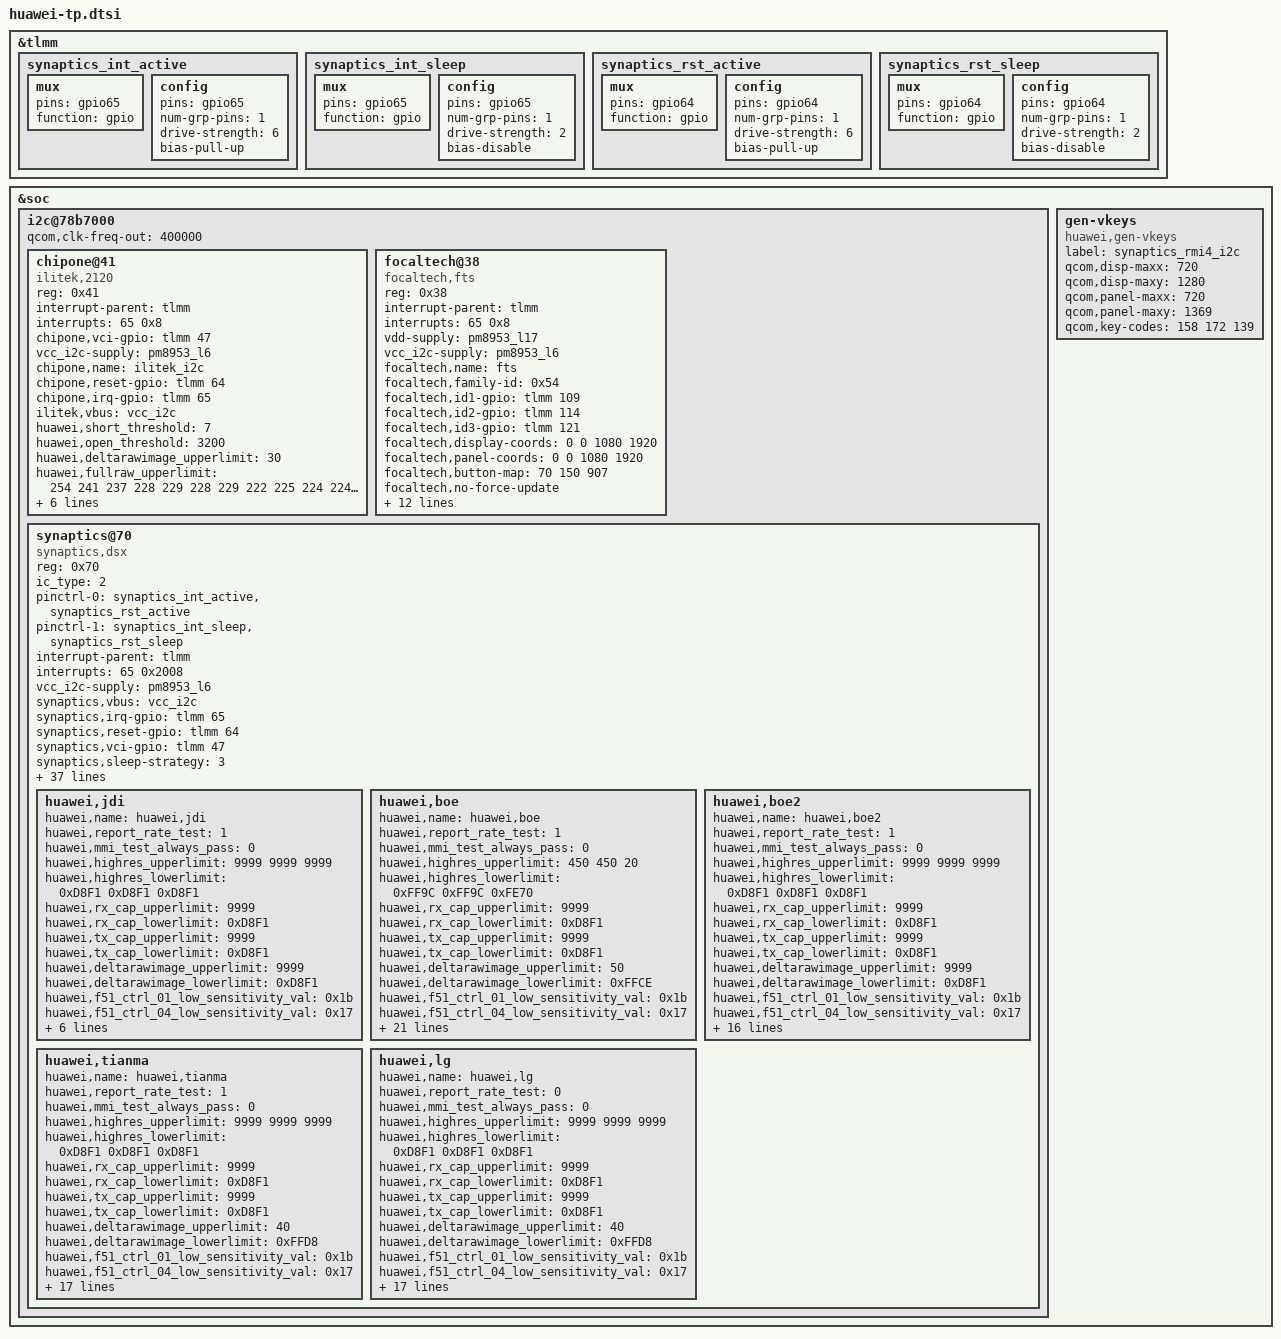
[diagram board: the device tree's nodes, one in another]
/* Modify JDI tp/lcd power on/off to reduce power consumption */
/* Modify JDI tp reset gpio pinctrl for power consumption */
/*Ath TP not working in glove mode*/
/* move l16 control to ATH device config file */
&tlmm {
	synaptics_int_active: synaptics_int_active{
			mux {
				pins = "gpio65";
				function =  "gpio";
			};
			config {
				pins = "gpio65";
				num-grp-pins = <1>;
				drive-strength = <6>;
				bias-pull-up;
		};
	};
	synaptics_int_sleep: synaptics_int_sleep {
			mux {
				pins = "gpio65";
				function =  "gpio";
			};
			config {
				pins = "gpio65";
				num-grp-pins = <1>;
				drive-strength = <2>;
				bias-disable;
		};
	};
	synaptics_rst_active: synaptics_rst_active {
			mux {
				pins = "gpio64";
				function =  "gpio";
			};
			config {
				pins = "gpio64";
				num-grp-pins = <1>;
				drive-strength = <6>;
				bias-pull-up;
			};
		};
	synaptics_rst_sleep: synaptics_rst_sleep {
			mux {
				pins = "gpio64";
				function =  "gpio";
			};
			config {
				pins = "gpio64";
				num-grp-pins = <1>;
				drive-strength = <2>;
				bias-disable;
		};
	};
};

&soc {
	i2c@78b7000 { /* BLSP1 QUP5 */
		status = "ok";
		#address-cells = <1>;
		#size-cells = <0>;
		qcom,clk-freq-out = <400000>;
		chipone@41{
			compatible = "ilitek,2120";
			reg = <0x41>;
			interrupt-parent = <&tlmm>;
			interrupts = <65 0x8>;
			chipone,vci-gpio = <&tlmm 47 0x0>;
			vcc_i2c-supply = <&pm8953_l6>;
			chipone,name = "ilitek_i2c";
			chipone,reset-gpio = <&tlmm 64 0x00>;
			chipone,irq-gpio = <&tlmm 65 0x00>;
			ilitek,vbus = "vcc_i2c";
			huawei,short_threshold = <7>;
			huawei,open_threshold = <3200>;
			huawei,deltarawimage_upperlimit = <30>;
			huawei,fullraw_upperlimit =
				<254 241 237 228 229 228 229 222 225 224 224 220 220 235 252
				247 234 232 219 219 220 220 216 218 217 216 214 213 228 246
				247 232 228 218 219 219 219 214 216 214 216 213 212 228 244
				247 232 228 218 220 218 219 214 216 214 214 212 212 226 244
				247 232 228 218 220 220 220 216 216 214 216 213 212 226 244
				247 231 228 219 218 219 219 214 217 214 216 213 212 226 244
				247 232 228 218 220 218 219 214 216 214 216 213 212 228 246
				247 232 228 219 219 218 219 214 216 216 216 213 212 226 244
				247 232 226 218 219 219 219 214 217 216 214 213 212 226 244
				247 231 226 218 219 218 218 214 216 214 214 213 212 228 244
				247 232 228 218 219 218 219 214 216 214 214 214 213 226 244
				247 231 226 218 219 218 219 216 216 214 214 214 213 228 246
				247 231 228 217 218 218 218 216 214 214 214 214 213 229 246
				249 235 230 219 222 222 222 219 218 218 218 218 217 231 248
				246 232 228 217 218 217 219 216 216 214 216 214 213 229 246
				247 231 226 217 218 218 219 216 214 214 216 216 214 230 246
				247 231 226 218 218 219 219 216 214 216 216 216 214 231 246
				247 231 226 217 218 217 218 217 216 214 216 214 214 230 246
				246 231 228 217 218 217 218 216 216 216 216 216 214 230 246
				247 231 225 217 218 217 218 216 216 214 216 216 214 231 247
				246 230 226 216 217 217 218 217 214 214 214 216 214 232 247
				246 230 226 217 218 217 218 216 214 214 214 216 214 233 246
				246 231 226 217 218 217 218 216 216 214 216 214 214 233 247
				246 231 225 216 218 217 217 216 214 214 216 216 214 229 246
				246 231 226 217 218 218 217 216 214 214 216 214 214 229 246
				246 231 226 218 218 218 218 216 214 214 214 216 214 228 246
				253 238 235 225 226 226 226 224 224 223 224 223 222 236 253>;

			huawei,fullraw_lowerlimit =
				<142 132 132 125 127 128 127 128 128 128 127 127 127 134 141
				139 128 129 121 124 124 123 124 125 125 124 123 123 130 137
				138 128 129 121 123 124 122 124 124 124 124 123 123 131 138
				138 128 128 120 123 124 123 124 124 125 124 123 122 130 136
				139 128 128 122 123 124 122 124 124 123 124 122 122 128 136
				138 128 128 121 123 123 122 124 124 124 123 122 122 127 135
				138 128 128 121 123 124 123 123 124 123 124 122 120 129 136
				139 128 128 121 123 124 123 124 124 125 123 121 120 128 134
				138 128 128 121 124 124 123 124 124 124 123 121 120 128 133
				136 128 128 121 124 124 122 123 124 122 122 121 119 127 133
				138 128 128 121 123 123 123 122 124 124 122 121 120 127 133
				137 128 128 121 123 124 122 124 124 123 123 121 121 129 135
				138 128 128 121 124 123 122 124 121 122 123 121 123 130 135
				138 129 130 123 124 125 124 125 125 126 125 126 124 130 136
				137 128 128 121 123 124 122 124 124 123 123 124 122 129 136
				137 128 128 121 123 124 122 123 124 123 123 124 123 130 136
				137 128 128 121 123 123 122 123 122 124 123 124 123 132 136
				138 128 128 121 123 123 122 124 124 124 124 124 123 132 136
				136 128 128 121 123 123 122 123 124 124 123 124 123 131 135
				136 128 127 121 122 123 122 124 124 123 124 124 123 131 136
				135 128 128 121 121 123 123 124 122 124 122 124 123 132 136
				133 128 128 121 122 124 122 124 121 123 123 124 123 132 135
				135 128 127 121 123 123 122 124 123 122 124 123 123 132 136
				134 128 126 121 121 124 122 124 122 122 124 123 122 129 134
				133 128 127 120 122 124 122 124 120 120 123 121 121 127 133
				134 128 126 121 121 122 123 123 120 121 121 122 121 127 132
				136 132 132 124 125 128 127 127 126 126 128 126 124 130 136>;

			huawei,rx_cap_upperlimit =
				<30 10 20 10 10 10 15 10 10 15 15 10 30 30
				30 10 20 10 10 10 15 10 10 15 15 10 30 30
				30 10 20 10 10 10 15 10 10 15 15 10 30 30
				30 10 20 10 10 10 15 10 10 15 15 10 30 30
				30 10 20 10 10 10 15 10 10 15 15 10 30 30
				30 10 20 10 10 10 15 10 10 15 15 10 30 30
				30 10 20 10 10 10 15 10 10 15 15 10 30 30
				30 10 20 10 10 10 15 10 10 15 15 10 30 30
				30 10 20 10 10 10 15 10 10 15 15 10 30 30
				30 10 20 10 10 10 15 10 10 15 15 10 30 30
				30 10 20 10 10 10 15 10 10 15 15 10 30 30
				30 10 20 10 10 10 15 10 10 15 15 10 30 30
				30 10 20 10 10 10 15 10 10 15 15 10 30 30
				30 10 20 10 10 10 15 10 10 15 15 10 30 30
				30 10 20 10 10 10 15 10 10 15 15 10 30 30
				30 10 20 10 10 10 15 10 10 15 15 10 30 30
				30 10 20 10 10 10 15 10 10 15 15 10 30 30
				30 10 20 10 10 10 15 10 10 15 15 10 30 30
				30 10 20 10 10 10 15 10 10 15 15 10 30 30
				30 10 20 10 10 10 15 10 10 15 15 10 30 30
				30 10 20 10 10 10 15 10 10 15 15 10 30 30
				30 10 20 10 10 10 15 10 10 15 15 10 30 30
				30 10 20 10 10 10 15 10 10 15 15 10 30 30
				30 10 20 10 10 10 15 10 10 15 15 10 30 30
				30 10 20 10 10 10 15 10 10 15 15 10 30 30
				30 10 20 10 10 10 15 10 10 15 15 10 30 30
				30 10 20 10 10 10 15 10 10 15 15 10 30 30>;

			huawei,tx_cap_upperlimit =
				<20 20 20 20 20 20 20 20 20 20 20 20 20 20 20
				10 10 10 10 10 10 10 10 10 10 10 10 10 10 10
				10 10 10 10 10 10 10 10 10 10 10 10 10 10 10
				10 10 10 10 10 10 10 10 10 10 10 10 10 10 10
				10 10 10 10 10 10 10 10 10 10 10 10 10 10 10
				10 10 10 10 10 10 10 10 10 10 10 10 10 10 10
				10 10 10 10 10 10 10 10 10 10 10 10 10 10 10
				10 10 10 10 10 10 10 10 10 10 10 10 10 10 10
				10 10 10 10 10 10 10 10 10 10 10 10 10 10 10
				10 10 10 10 10 10 10 10 10 10 10 10 10 10 10
				10 10 10 10 10 10 10 10 10 10 10 10 10 10 10
				10 10 10 10 10 10 10 10 10 10 10 10 10 10 10
				15 15 15 15 15 15 15 15 15 15 15 15 15 15 15
				15 15 15 15 15 15 15 15 15 15 15 15 15 15 15
				10 10 10 10 10 10 10 10 10 10 10 10 10 10 10
				10 10 10 10 10 10 10 10 10 10 10 10 10 10 10
				10 10 10 10 10 10 10 10 10 10 10 10 10 10 10
				10 10 10 10 10 10 10 10 10 10 10 10 10 10 10
				10 10 10 10 10 10 10 10 10 10 10 10 10 10 10
				10 10 10 10 10 10 10 10 10 10 10 10 10 10 10
				10 10 10 10 10 10 10 10 10 10 10 10 10 10 10
				10 10 10 10 10 10 10 10 10 10 10 10 10 10 10
				10 10 10 10 10 10 10 10 10 10 10 10 10 10 10
				10 10 10 10 10 10 10 10 10 10 10 10 10 10 10
				10 10 10 10 10 10 10 10 10 10 10 10 10 10 10
				20 20 20 20 20 20 20 20 20 20 20 20 20 20 20>;
		};
		focaltech@38 {
		compatible = "focaltech,fts";
		reg = <0x38>;
		interrupt-parent = <&tlmm>;
		interrupts = <65 0x8>;
		vdd-supply = <&pm8953_l17>;
		vcc_i2c-supply = <&pm8953_l6>;
		focaltech,name = "fts";
		focaltech,family-id = <0x54>;
		//focaltech,reset-gpio = <&tlmm 64 0x00>;
		//focaltech,irq-gpio =<&tlmm 65 0x00>;
		focaltech,id1-gpio = <&tlmm 109 0x00>;
		focaltech,id2-gpio = <&tlmm 114 0x00>;
		focaltech,id3-gpio = <&tlmm 121 0x00>;
		focaltech,display-coords = <0 0 1080 1920>;
		focaltech,panel-coords = <0 0 1080 1920>;
		focaltech,button-map= <70 150 907>;
		focaltech,no-force-update;
		focaltech,i2c-pull-up;
		focaltech,group-id = <1>;
		focaltech,hard-reset-delay-ms = <20>;
		focaltech,soft-reset-delay-ms = <150>;
		focaltech,num-max-touches = <10>;
		focaltech,fw-name = "FT_Upgrade_App.i";
		focaltech,fw-delay-aa-ms = <50>;
		focaltech,fw-delay-55-ms = <30>;
		focaltech,fw-upgrade-id1 = <0x79>;
		focaltech,fw-upgrade-id2 = <0x03>;
		focaltech,fw-delay-readid-ms = <10>;
		focaltech,fw-delay-era-flsh-ms = <2000>;
		};
		synaptics@70 {
			compatible = "synaptics,dsx";
			reg = <0x70>;

			/* SYNAPTICS_S3207 = 0 */
			/* SYNAPTICS_S3350 = 1 */
			/* SYNAPTICS_S3320 = 2 */
			/* SYNAPTICS_S3718 = 3 */
			ic_type = <2>;

			pinctrl-names = "active","sleep";
			pinctrl-0 = <&synaptics_int_active &synaptics_rst_active>;
			pinctrl-1 = <&synaptics_int_sleep &synaptics_rst_sleep>;

			interrupt-parent = <&tlmm>;
			interrupts = <65 0x2008>;
			//vdd-supply = <&pm8953_l17>;
			vcc_i2c-supply = <&pm8953_l6>;
			/* Some of qcom's param will not be replaced by huawei in dtb, */
			/* just ignore them:such as "pinctrl-names","pinctrl-0","pinctrl-1", */
			/* "synaptics,display-coords","synaptics,panel-coords","synaptics,i2c-pull-up", */
			/* "synaptics,power-down","synaptics,disable-gpios"*/
			//synaptics,vdd = "vdd";
			synaptics,vbus = "vcc_i2c";
			synaptics,irq-gpio = <&tlmm 65 0x2008>;
			synaptics,reset-gpio = <&tlmm 64 0x0>;
			synaptics,vci-gpio = <&tlmm 47 0x0>;

			/* synaptics,sleep/wake strategy */

			/* SLEEP_STRATEGY_DEEP_SLEEP    : 0*/
			/* SLEEP_STRATEGY_POWER_DOWN    : 1*/
			/* SLEEP_STRATEGY_KEEP_WAKE     : 2*/
			/* SLEEP_STRATEGY_ALWAYS_RESET  : 3*/
			synaptics,sleep-strategy = <3>;

			synaptics,lcd-x = <1080>;
			synaptics,lcd-y = <1920>;
			synaptics,lcd-all = <1920>;
			synaptics,virtual_keys = /* KeyCode CenterX CenterY Width Height */
				/* KEY_BACK */
				<158 142 1342 150 100
				/* KEY_HOME(172) */
				172 360 1342 150 100
				/* KEY_MENU */
				139 578 1342 150 100>;
			synaptics,shutdown_flag = <1>;
			synaptics,appinfo_display_flag = <1>;
			/* SYNAPTICS_WAKE_UP_GESTURE_FLAG:'1'->enabled,'0'->disabled */
			/*IC flash is not enough for holster,so fw del one gesture*/
			synaptics,gesture_enabled = <0>;
			/* Gestures that supported:                           */
			/* bit0  Double tap                                        */
			/* bit1  Single finger slide from left to right     */
			/* bit2  Single finger slide from right to left     */
			/* bit3  Single finger slide from top to bottom  */
			/* bit4  Single finger slide from bottom to top  */
			/* bit5  Double finger slide from top to bottom--disable for holster*/
			/* bit6  Single finger slide circle                     */
			/* bit7  Single finger write letter c                  */
			/* bit8  Single finger write letter e                  */
			/* bit9  Single finger write letter m                 */
			/* bit10 Single finger write letter w                 */
			/* bit11 Palm off screen                                */
			synaptics,easy_wakeup_supported_gestures = <0xF81>;

			/*Defination of report key value  for different gestures*/
			synaptics,easy_wakeup_gesture_keys =
			<	59 /*0.Double tap:                                  KEY_F1*/
				60 /*1.Single finger slide from left to right:      KEY_F2*/
				61 /*2.Single finger slide from right to left:      KEY_F3*/
				62 /*3.Single finger slide from top to bottom:      KEY_F4*/
				63 /*4.Single finger slide from bottom to top:      KEY_F5*/
				64 /*5.Single finger slide circle clockwise:        KEY_F6*/
				65 /*6.Single finger slide circle counter-clockwise:KEY_F7*/
				66 /*7.Single finger write letter c:                KEY_F8*/
				67 /*8.Single finger write letter e:                KEY_F9*/
				68 /*9.Single finger write letter m:                KEY_F10*/
				87 /*10.Single finger write letter w:               KEY_F11*/
				88 /*11.Palm off screen:                            KEY_F12*/
			>;

			/* Double-tap-zone defined by huawei */
			/* Shielded area is:1cm left,1cm right,3cm up,2cm down */
			huawei,dtz_x0 = <1>;
			huawei,dtz_y0 = <1>;
			huawei,dtz_x1 = <1080>;
			huawei,dtz_y1 = <1920>;

			/* GLOVE FLAG default state:'1'->enabled,'0'->disabled*/
			synaptics,glove_enabled = <0>;
			/*After reduce power-consumption by exit reduce mode,*/
			/*we have to reduce f-r rate to make sure gesture work fine*/
			synaptics,fast_relax_gesture = <0>;
			/*Holster support flag*/
			synaptics,holster_supported = <1>;
			synaptics,glove_edge_switch_supported = <0>;
			synaptics,grip_algorithm_supported = <0>;
			synaptics,grip_algorithm_enabled = <0>;
			huawei,grip_left_lsb = <0x32>;
			huawei,grip_left_msb = <0x0>;
			huawei,grip_right_lsb = <0x1A>;
			huawei,grip_right_msb = <0x04>;
			synaptics,roi_supported = <1>;
			synaptics,tx_rx_supported = <1>;
			huawei,tddi_esd_flag = <1>;
			/*dwt represent doze wakeup threshold in gesture mode*/
			synaptics,ofilm_dwt = <30>;
			synaptics,truly_dwt = <30>;
			synaptics,junda_dwt = <30>;

			synaptics,reset-on-status = <0>;
			synaptics,power-delay-ms = <160>;
			synaptics,reset-delay-ms = <200>;
			synaptics,reset-active-ms = <10>;
			synaptics,product_name = "cannes";

			/*capacitance self-adapt*/
			huawei,jdi {
				huawei,name = "huawei,jdi";
				huawei,report_rate_test = <1>; /* 0:disable test, 1:enable test */
				huawei,mmi_test_always_pass = <0>;

				huawei,highres_upperlimit = <9999 9999 9999>;
				huawei,highres_lowerlimit = <0xD8F1 0xD8F1 0xD8F1>;/* 0xD8F1 == -9999 */

				huawei,rx_cap_upperlimit = <9999>;
				huawei,rx_cap_lowerlimit = <0xD8F1>;

				huawei,tx_cap_upperlimit = <9999>;
				huawei,tx_cap_lowerlimit = <0xD8F1>;

				huawei,deltarawimage_upperlimit = <9999>;
				huawei,deltarawimage_lowerlimit = <0xD8F1>;

				huawei,f51_ctrl_01_low_sensitivity_val = <0x1b>;
				huawei,f51_ctrl_04_low_sensitivity_val = <0x17>;
				huawei,f01_ctrl_05_low_sensitivity_val = <0x05>;
				huawei,f01_ctrl_09_low_sensitivity_val = <0x04>;

				huawei,fullraw_upperlimit =
					<9999 9999 9999 9999 9999 9999 9999 9999 9999 9999 9999 9999 9999 9999 9999 9999 9999 9999 9999 9999 9999 9999 9999 9999 9999 9999 9999 9999
					9999 9999 9999 9999 9999 9999 9999 9999 9999 9999 9999 9999 9999 9999 9999 9999 9999 9999 9999 9999 9999 9999 9999 9999 9999 9999 9999 9999
					9999 9999 9999 9999 9999 9999 9999 9999 9999 9999 9999 9999 9999 9999 9999 9999 9999 9999 9999 9999 9999 9999 9999 9999 9999 9999 9999 9999
					9999 9999 9999 9999 9999 9999 9999 9999 9999 9999 9999 9999 9999 9999 9999 9999 9999 9999 9999 9999 9999 9999 9999 9999 9999 9999 9999 9999
					9999 9999 9999 9999 9999 9999 9999 9999 9999 9999 9999 9999 9999 9999 9999 9999 9999 9999 9999 9999 9999 9999 9999 9999 9999 9999 9999 9999
					9999 9999 9999 9999 9999 9999 9999 9999 9999 9999 9999 9999 9999 9999 9999 9999 9999 9999 9999 9999 9999 9999 9999 9999 9999 9999 9999 9999
					9999 9999 9999 9999 9999 9999 9999 9999 9999 9999 9999 9999 9999 9999 9999 9999 9999 9999 9999 9999 9999 9999 9999 9999 9999 9999 9999 9999
					9999 9999 9999 9999 9999 9999 9999 9999 9999 9999 9999 9999 9999 9999 9999 9999 9999 9999 9999 9999 9999 9999 9999 9999 9999 9999 9999 9999
					9999 9999 9999 9999 9999 9999 9999 9999 9999 9999 9999 9999 9999 9999 9999 9999 9999 9999 9999 9999 9999 9999 9999 9999 9999 9999 9999 9999
					9999 9999 9999 9999 9999 9999 9999 9999 9999 9999 9999 9999 9999 9999 9999 9999 9999 9999 9999 9999 9999 9999 9999 9999 9999 9999 9999 9999
					9999 9999 9999 9999 9999 9999 9999 9999 9999 9999 9999 9999 9999 9999 9999 9999 9999 9999 9999 9999 9999 9999 9999 9999 9999 9999 9999 9999
					9999 9999 9999 9999 9999 9999 9999 9999 9999 9999 9999 9999 9999 9999 9999 9999 9999 9999 9999 9999 9999 9999 9999 9999 9999 9999 9999 9999
					9999 9999 9999 9999 9999 9999 9999 9999 9999 9999 9999 9999 9999 9999 9999 9999 9999 9999 9999 9999 9999 9999 9999 9999 9999 9999 9999 9999
					9999 9999 9999 9999 9999 9999 9999 9999 9999 9999 9999 9999 9999 9999 9999 9999 9999 9999 9999 9999 9999 9999 9999 9999 9999 9999 9999 9999
					9999 9999 9999 9999 9999 9999 9999 9999 9999 9999 9999 9999 9999 9999 9999 9999 9999 9999 9999 9999 9999 9999 9999 9999 9999 9999 9999 9999
					9999 9999 9999 9999 9999 9999 9999 9999 9999 9999 9999 9999 9999 9999 9999 9999 9999 9999 9999 9999 9999 9999 9999 9999 9999 9999 9999 9999>;

				huawei,fullraw_lowerlimit =
					<0 0 0 0 0 0 0 0 0 0 0 0 0 0 0 0 0 0 0 0 0 0 0 0 0 0 0 0
					0 0 0 0 0 0 0 0 0 0 0 0 0 0 0 0 0 0 0 0 0 0 0 0 0 0 0 0
					0 0 0 0 0 0 0 0 0 0 0 0 0 0 0 0 0 0 0 0 0 0 0 0 0 0 0 0
					0 0 0 0 0 0 0 0 0 0 0 0 0 0 0 0 0 0 0 0 0 0 0 0 0 0 0 0
					0 0 0 0 0 0 0 0 0 0 0 0 0 0 0 0 0 0 0 0 0 0 0 0 0 0 0 0
					0 0 0 0 0 0 0 0 0 0 0 0 0 0 0 0 0 0 0 0 0 0 0 0 0 0 0 0
					0 0 0 0 0 0 0 0 0 0 0 0 0 0 0 0 0 0 0 0 0 0 0 0 0 0 0 0
					0 0 0 0 0 0 0 0 0 0 0 0 0 0 0 0 0 0 0 0 0 0 0 0 0 0 0 0
					0 0 0 0 0 0 0 0 0 0 0 0 0 0 0 0 0 0 0 0 0 0 0 0 0 0 0 0
					0 0 0 0 0 0 0 0 0 0 0 0 0 0 0 0 0 0 0 0 0 0 0 0 0 0 0 0
					0 0 0 0 0 0 0 0 0 0 0 0 0 0 0 0 0 0 0 0 0 0 0 0 0 0 0 0
					0 0 0 0 0 0 0 0 0 0 0 0 0 0 0 0 0 0 0 0 0 0 0 0 0 0 0 0
					0 0 0 0 0 0 0 0 0 0 0 0 0 0 0 0 0 0 0 0 0 0 0 0 0 0 0 0
					0 0 0 0 0 0 0 0 0 0 0 0 0 0 0 0 0 0 0 0 0 0 0 0 0 0 0 0
					0 0 0 0 0 0 0 0 0 0 0 0 0 0 0 0 0 0 0 0 0 0 0 0 0 0 0 0
					0 0 0 0 0 0 0 0 0 0 0 0 0 0 0 0 0 0 0 0 0 0 0 0 0 0 0 0>;
			};

			huawei,boe {
				huawei,name = "huawei,boe";
				huawei,report_rate_test = <1>; /* 0:disable test, 1:enable test */
				huawei,mmi_test_always_pass = <0>;

				huawei,highres_upperlimit = <450 450 20>;
				huawei,highres_lowerlimit = <0xFF9C 0xFF9C 0xFE70>;/*0xFF9C == -100 0xFE70 == -400 */

				huawei,rx_cap_upperlimit = <9999>;
				huawei,rx_cap_lowerlimit = <0xD8F1>;

				huawei,tx_cap_upperlimit = <9999>;
				huawei,tx_cap_lowerlimit = <0xD8F1>;

				huawei,deltarawimage_upperlimit = <50>;
				huawei,deltarawimage_lowerlimit = <0xFFCE>;

				huawei,f51_ctrl_01_low_sensitivity_val = <0x1b>;
				huawei,f51_ctrl_04_low_sensitivity_val = <0x17>;
				huawei,f01_ctrl_05_low_sensitivity_val = <0x05>;
				huawei,f01_ctrl_09_low_sensitivity_val = <0x04>;

				huawei,roi_control_addr_offset = <2>;
				huawei,roi_control_bit = <0>;
				huawei,roi_data_addr_offset = <24>;

				huawei,holster_switch_offset = <0>;
				huawei,set_effective_window_offset = <15>;
				huawei,holster_switch_glove_offset = <25>;
				huawei,support_set_window = <0>;
				huawei,support_3320short_test = <1>;
				huawei,trx_short_array_num = <4>;
				huawei,short_circuit_array = <0x00 0x00 0x00 0x00>;

				huawei,fullraw_upperlimit =
					<3447 3363 3309 3248 3208 3193 3177 3184 3190 3195 3194 3244 3314 3373 3487
					3306 3187 3126 3080 3043 3027 3013 3015 3013 3046 3025 3073 3136 3177 3289
					3314 3181 3111 3072 3032 3022 3016 3016 3007 3042 3025 3076 3111 3169 3298
					3316 3190 3117 3060 3020 3016 3020 3027 3016 3042 3030 3064 3111 3169 3306
					3321 3177 3114 3069 3025 3019 3025 3032 3022 3046 3043 3072 3116 3174 3308
					3328 3187 3117 3067 3030 3022 3027 3033 3027 3054 3046 3079 3117 3174 3312
					3330 3194 3121 3067 3030 3026 3032 3042 3027 3052 3050 3086 3138 3208 3312
					3328 3195 3126 3069 3036 3026 3037 3050 3037 3056 3057 3104 3168 3235 3309
					3314 3188 3120 3060 3033 3016 3037 3046 3033 3045 3052 3090 3168 3231 3292
					3322 3184 3123 3072 3033 3030 3037 3049 3033 3056 3064 3110 3178 3244 3302
					3315 3181 3114 3072 3026 3026 3032 3042 3027 3052 3063 3109 3169 3230 3292
					3312 3181 3114 3062 3027 3026 3032 3037 3027 3052 3050 3094 3153 3214 3282
					3306 3177 3106 3049 3020 3015 3022 3030 3019 3039 3045 3080 3141 3198 3274
					3295 3166 3094 3039 3010 3007 3013 3020 3016 3036 3033 3064 3136 3200 3262
					3288 3158 3091 3032 3004 3002 3002 3009 3007 3027 3015 3050 3109 3181 3253
					3274 3147 3079 3019 3000 2992 2989 3006 2996 3016 3009 3030 3073 3144 3244
					3261 3132 3062 3004 2995 2979 2978 2992 2983 3004 2992 3016 3057 3117 3230
					3241 3110 3050 2985 2972 2962 2958 2976 2968 2992 2976 3000 3025 3091 3208
					3228 3091 3033 2976 2953 2946 2943 2961 2953 2976 2961 2988 3009 3072 3193
					3207 3076 3020 2958 2943 2935 2929 2943 2942 2965 2941 2970 2996 3052 3171
					3184 3057 3007 2942 2931 2923 2911 2923 2929 2952 2922 2958 2995 3043 3151
					3158 3045 2990 2936 2928 2912 2901 2905 2914 2936 2904 2942 2989 3042 3132
					3134 3050 2990 2942 2935 2920 2906 2892 2896 2918 2884 2923 2985 3032 3109
					3116 3050 2989 2949 2936 2920 2908 2896 2881 2904 2868 2906 2968 3015 3084
					3116 3049 2979 2946 2938 2925 2908 2904 2888 2886 2875 2914 2973 3025 3060
					3109 3045 2998 2952 2938 2922 2911 2904 2894 2892 2881 2932 2998 3049 3043
					3314 3253 3207 3163 3130 3110 3109 3144 3088 3099 3088 3127 3195 3238 3253>;

				huawei,fullraw_lowerlimit =
					<1915 1738 1881 1856 1840 1839 1832 1840 1829 1814 1829 1826 1875 1910 1870
					1830 1671 1799 1768 1742 1727 1724 1713 1718 1712 1692 1718 1751 1793 1791
					1841 1679 1773 1743 1699 1695 1680 1684 1660 1679 1671 1696 1699 1742 1753
					1847 1687 1769 1760 1763 1756 1756 1747 1697 1744 1731 1756 1788 1830 1820
					1854 1693 1822 1796 1783 1783 1776 1780 1762 1748 1767 1793 1807 1850 1825
					1857 1700 1825 1789 1773 1756 1743 1755 1748 1751 1743 1732 1781 1834 1808
					1860 1702 1826 1784 1768 1751 1737 1751 1744 1747 1741 1730 1778 1830 1807
					1861 1706 1832 1791 1773 1756 1745 1758 1753 1756 1749 1738 1787 1840 1826
					1855 1700 1824 1799 1786 1786 1780 1789 1776 1762 1781 1803 1816 1863 1830
					1861 1711 1830 1807 1792 1784 1783 1774 1781 1763 1760 1788 1816 1868 1832
					1857 1711 1807 1760 1741 1720 1706 1715 1707 1708 1696 1685 1728 1780 1788
					1763 1712 1668 1631 1608 1592 1592 1579 1588 1585 1569 1599 1637 1686 1704
					1584 1569 1532 1492 1480 1468 1460 1479 1480 1491 1489 1492 1545 1608 1631
					1847 1707 1756 1720 1693 1679 1677 1664 1672 1668 1650 1677 1712 1760 1770
					1843 1704 1767 1737 1732 1732 1730 1717 1724 1718 1699 1725 1760 1805 1812
					1836 1700 1753 1732 1692 1687 1672 1684 1660 1664 1648 1675 1680 1722 1762
					1804 1697 1760 1730 1707 1697 1699 1690 1702 1700 1685 1716 1752 1801 1796
					1824 1690 1793 1769 1749 1737 1736 1724 1732 1725 1708 1735 1766 1812 1791
					1814 1687 1737 1707 1690 1682 1685 1685 1685 1685 1674 1668 1702 1751 1760
					1805 1682 1736 1722 1695 1679 1675 1661 1666 1656 1635 1657 1686 1725 1733
					1624 1578 1529 1494 1472 1462 1466 1457 1469 1469 1455 1486 1523 1574 1594
					1787 1674 1758 1732 1713 1704 1700 1696 1686 1684 1682 1679 1699 1748 1748
					1763 1668 1725 1695 1668 1651 1639 1636 1630 1634 1612 1636 1648 1692 1712
					1730 1660 1688 1657 1629 1612 1596 1609 1585 1588 1572 1594 1598 1641 1684
					1700 1635 1556 1553 1543 1536 1532 1552 1556 1553 1559 1590 1601 1656 1629
					1718 1718 1659 1606 1592 1584 1572 1596 1562 1562 1563 1563 1587 1640 1659
					1616 1599 1554 1517 1491 1488 1473 1476 1471 1475 1460 1484 1512 1548 1554>;
				huawei,tx_to_tx_limit =
					<275 275 275 275 275 275 275 275 275 275 275 275 275 275 275
					200 200	200 200	200 200	200 200 200 200 200 200 200 200 200
					200 200	200 200	200 200	200 200	200 200	200 200	200 200	200
					200 200	200 200	200 200	200 200	200 200	200 200	200 200	200
					200 200	200 200	200 200	200 200	200 200	200 200	200 200	200
					200 200	200 200	200 200	200 200	200 200	200 200	200 200	200
					200 200	200 200	200 200	200 200	200 200	200 200	200 200	200
					200 200	200 200	200 200	200 200	200 200	200 200	200 200	200
					200 200	200 200	200 200	200 200	200 200	200 200	200 200	200
					200 200	200 200	200 200	200 200	200 200	200 200	200 200	200
					200 200	200 200	200 200	200 200	200 200	200 200	200 200	200
					200 200	200 200	200 200	200 200	200 200	200 200	200 200	200
					200 200	200 200	200 200	200 200	200 200	200 200	200 200	200
					200 200	200 200	200 200	200 200	200 200	200 200	200 200	200
					200 200	200 200	200 200	200 200	200 200	200 200	200 200	200
					200 200	200 200	200 200	200 200	200 200	200 200	200 200	200
					200 200	200 200	200 200	200 200	200 200	200 200	200 200	200
					200 200	200 200	200 200	200 200	200 200	200 200	200 200	200
					200 200	200 200	200 200	200 200	200 200	200 200	200 200	200
					200 200	200 200	200 200	200 200	200 200	200 200	200 200	200
					200 200	200 200	200 200	200 200	200 200	200 200	200 200	200
					200 200	200 200	200 200	200 200	200 200	200 200	200 200	200
					200 200	200 200	200 200	200 200	200 200	200 200	200 200	200
					200 200	200 200	200 200	200 200	200 200	200 200	200 200	200
					200 200	200 200	200 200	200 200	200 200	200 200	200 200	200
					350 350	350 350	350 350	350 350	350 350	350 350	350 350	350>;
				huawei,rx_to_rx_limit =
					<250 250 250 250 250 250 250 250 250 250 250 250 250 250
					250 250 250 250 250 250 250 250 250 250 250 250 250 250
					250 250 250 250 250 250 250 250 250 250 250 250 250 250
					250 250 250 250 250 250 250 250 250 250 250 250 250 250
					250 250 250 250 250 250 250 250 250 250 250 250 250 250
					250 250 250 250 250 250 250 250 250 250 250 250 250 250
					250 250 250 250 250 250 250 250 250 250 250 250 250 250
					250 250 250 250 250 250 250 250 250 250 250 250 250 250
					250 250 250 250 250 250 250 250 250 250 250 250 250 250
					250 250 250 250 250 250 250 250 250 250 250 250 250 250
					250 250 250 250 250 250 250 250 250 250 250 250 250 250
					250 250 250 250 250 250 250 250 250 250 250 250 250 250
					250 250 250 250 250 250 250 250 250 250 250 250 250 250
					250 250 250 250 250 250 250 250 250 250 250 250 250 250
					250 250 250 250 250 250 250 250 250 250 250 250 250 250
					250 250 250 250 250 250 250 250 250 250 250 250 250 250
					250 250 250 250 250 250 250 250 250 250 250 250 250 250
					250 250 250 250 250 250 250 250 250 250 250 250 250 250
					250 250 250 250 250 250 250 250 250 250 250 250 250 250
					250 250 250 250 250 250 250 250 250 250 250 250 250 250
					250 250 250 250 250 250 250 250 250 250 250 250 250 250
					250 250 250 250 250 250 250 250 250 250 250 250 250 250
					250 250 250 250 250 250 250 250 250 250 250 250 250 250
					250 250 250 250 250 250 250 250 250 250 250 250 250 250
					250 250 250 250 250 250 250 250 250 250 250 250 250 250
					250 250 250 250 250 250 250 250 250 250 250 250 250 250
					250 250 250 250 250 250 250 250 250 250 250 250 250 250>;
			};
			huawei,boe2{
				huawei,name = "huawei,boe2";
				huawei,report_rate_test = <1>; /* 0:disable test, 1:enable test */
				// if is config item is set to 1, the mmi test will always return pass
				huawei,mmi_test_always_pass = <0>;

				huawei,highres_upperlimit = <9999 9999 9999>;
				huawei,highres_lowerlimit = <0xD8F1 0xD8F1 0xD8F1>;/* 0xD8F1 == -9999 */

				huawei,rx_cap_upperlimit = <9999>;
				huawei,rx_cap_lowerlimit = <0xD8F1>;

				huawei,tx_cap_upperlimit = <9999>;
				huawei,tx_cap_lowerlimit = <0xD8F1>;

				huawei,deltarawimage_upperlimit = <9999>;
				huawei,deltarawimage_lowerlimit = <0xD8F1>;

				huawei,f51_ctrl_01_low_sensitivity_val = <0x1b>;
				huawei,f51_ctrl_04_low_sensitivity_val = <0x17>;
				huawei,f01_ctrl_05_low_sensitivity_val = <0x05>;
				huawei,f01_ctrl_09_low_sensitivity_val = <0x04>;

				huawei,roi_control_addr_offset = <12>;
				huawei,roi_control_bit = <0>;
				huawei,roi_data_addr_offset = <0>;

				huawei,holster_switch_offset = <9>;
				huawei,set_effective_window_offset = <8>;
				huawei,support_set_window = <0>;

				huawei,fullraw_upperlimit =
					<9999 9999 9999 9999 9999 9999 9999 9999 9999 9999 9999 9999 9999 9999 9999 9999 9999 9999 9999 9999 9999 9999 9999 9999 9999 9999 9999 9999 9999 9999
					9999 9999 9999 9999 9999 9999 9999 9999 9999 9999 9999 9999 9999 9999 9999 9999 9999 9999 9999 9999 9999 9999 9999 9999 9999 9999 9999 9999 9999 9999
					9999 9999 9999 9999 9999 9999 9999 9999 9999 9999 9999 9999 9999 9999 9999 9999 9999 9999 9999 9999 9999 9999 9999 9999 9999 9999 9999 9999 9999 9999
					9999 9999 9999 9999 9999 9999 9999 9999 9999 9999 9999 9999 9999 9999 9999 9999 9999 9999 9999 9999 9999 9999 9999 9999 9999 9999 9999 9999 9999 9999
					9999 9999 9999 9999 9999 9999 9999 9999 9999 9999 9999 9999 9999 9999 9999 9999 9999 9999 9999 9999 9999 9999 9999 9999 9999 9999 9999 9999 9999 9999
					9999 9999 9999 9999 9999 9999 9999 9999 9999 9999 9999 9999 9999 9999 9999 9999 9999 9999 9999 9999 9999 9999 9999 9999 9999 9999 9999 9999 9999 9999
					9999 9999 9999 9999 9999 9999 9999 9999 9999 9999 9999 9999 9999 9999 9999 9999 9999 9999 9999 9999 9999 9999 9999 9999 9999 9999 9999 9999 9999 9999
					9999 9999 9999 9999 9999 9999 9999 9999 9999 9999 9999 9999 9999 9999 9999 9999 9999 9999 9999 9999 9999 9999 9999 9999 9999 9999 9999 9999 9999 9999
					9999 9999 9999 9999 9999 9999 9999 9999 9999 9999 9999 9999 9999 9999 9999 9999 9999 9999 9999 9999 9999 9999 9999 9999 9999 9999 9999 9999 9999 9999
					9999 9999 9999 9999 9999 9999 9999 9999 9999 9999 9999 9999 9999 9999 9999 9999 9999 9999 9999 9999 9999 9999 9999 9999 9999 9999 9999 9999 9999 9999
					9999 9999 9999 9999 9999 9999 9999 9999 9999 9999 9999 9999 9999 9999 9999 9999 9999 9999 9999 9999 9999 9999 9999 9999 9999 9999 9999 9999 9999 9999
					9999 9999 9999 9999 9999 9999 9999 9999 9999 9999 9999 9999 9999 9999 9999 9999 9999 9999 9999 9999 9999 9999 9999 9999 9999 9999 9999 9999 9999 9999
					9999 9999 9999 9999 9999 9999 9999 9999 9999 9999 9999 9999 9999 9999 9999 9999 9999 9999 9999 9999 9999 9999 9999 9999 9999 9999 9999 9999 9999 9999
					9999 9999 9999 9999 9999 9999 9999 9999 9999 9999 9999 9999 9999 9999 9999 9999 9999 9999 9999 9999 9999 9999 9999 9999 9999 9999 9999 9999 9999 9999
					9999 9999 9999 9999 9999 9999 9999 9999 9999 9999 9999 9999 9999 9999 9999 9999 9999 9999 9999 9999 9999 9999 9999 9999 9999 9999 9999 9999 9999 9999
					9999 9999 9999 9999 9999 9999 9999 9999 9999 9999 9999 9999 9999 9999 9999 9999 9999 9999 9999 9999 9999 9999 9999 9999 9999 9999 9999 9999 9999 9999
					9999 9999 9999 9999 9999 9999 9999 9999 9999 9999 9999 9999 9999 9999 9999 9999 9999 9999 9999 9999 9999 9999 9999 9999 9999 9999 9999 9999 9999 9999
					9999 9999 9999 9999 9999 9999 9999 9999 9999 9999 9999 9999 9999 9999 9999 9999 9999 9999 9999 9999 9999 9999 9999 9999 9999 9999 9999 9999 9999 9999>;

				huawei,fullraw_lowerlimit =
					<0 0 0 0 0 0 0 0 0 0 0 0 0 0 0 0 0 0 0 0 0 0 0 0 0 0 0 0 0 0
					0 0 0 0 0 0 0 0 0 0 0 0 0 0 0 0 0 0 0 0 0 0 0 0 0 0 0 0 0 0
					0 0 0 0 0 0 0 0 0 0 0 0 0 0 0 0 0 0 0 0 0 0 0 0 0 0 0 0 0 0
					0 0 0 0 0 0 0 0 0 0 0 0 0 0 0 0 0 0 0 0 0 0 0 0 0 0 0 0 0 0
					0 0 0 0 0 0 0 0 0 0 0 0 0 0 0 0 0 0 0 0 0 0 0 0 0 0 0 0 0 0
					0 0 0 0 0 0 0 0 0 0 0 0 0 0 0 0 0 0 0 0 0 0 0 0 0 0 0 0 0 0
					0 0 0 0 0 0 0 0 0 0 0 0 0 0 0 0 0 0 0 0 0 0 0 0 0 0 0 0 0 0
					0 0 0 0 0 0 0 0 0 0 0 0 0 0 0 0 0 0 0 0 0 0 0 0 0 0 0 0 0 0
					0 0 0 0 0 0 0 0 0 0 0 0 0 0 0 0 0 0 0 0 0 0 0 0 0 0 0 0 0 0
					0 0 0 0 0 0 0 0 0 0 0 0 0 0 0 0 0 0 0 0 0 0 0 0 0 0 0 0 0 0
					0 0 0 0 0 0 0 0 0 0 0 0 0 0 0 0 0 0 0 0 0 0 0 0 0 0 0 0 0 0
					0 0 0 0 0 0 0 0 0 0 0 0 0 0 0 0 0 0 0 0 0 0 0 0 0 0 0 0 0 0
					0 0 0 0 0 0 0 0 0 0 0 0 0 0 0 0 0 0 0 0 0 0 0 0 0 0 0 0 0 0
					0 0 0 0 0 0 0 0 0 0 0 0 0 0 0 0 0 0 0 0 0 0 0 0 0 0 0 0 0 0
					0 0 0 0 0 0 0 0 0 0 0 0 0 0 0 0 0 0 0 0 0 0 0 0 0 0 0 0 0 0
					0 0 0 0 0 0 0 0 0 0 0 0 0 0 0 0 0 0 0 0 0 0 0 0 0 0 0 0 0 0
					0 0 0 0 0 0 0 0 0 0 0 0 0 0 0 0 0 0 0 0 0 0 0 0 0 0 0 0 0 0
					0 0 0 0 0 0 0 0 0 0 0 0 0 0 0 0 0 0 0 0 0 0 0 0 0 0 0 0 0 0>;
				huawei,tx_to_tx_limit =
					<9999 9999 9999 9999 9999 9999 9999 9999 9999 9999 9999 9999 9999 9999 9999 9999 9999 9999 9999 9999 9999 9999 9999 9999 9999 9999 9999 9999 9999 9999
					9999 9999 9999 9999 9999 9999 9999 9999 9999 9999 9999 9999 9999 9999 9999 9999 9999 9999 9999 9999 9999 9999 9999 9999 9999 9999 9999 9999 9999 9999
					9999 9999 9999 9999 9999 9999 9999 9999 9999 9999 9999 9999 9999 9999 9999 9999 9999 9999 9999 9999 9999 9999 9999 9999 9999 9999 9999 9999 9999 9999
					9999 9999 9999 9999 9999 9999 9999 9999 9999 9999 9999 9999 9999 9999 9999 9999 9999 9999 9999 9999 9999 9999 9999 9999 9999 9999 9999 9999 9999 9999
					9999 9999 9999 9999 9999 9999 9999 9999 9999 9999 9999 9999 9999 9999 9999 9999 9999 9999 9999 9999 9999 9999 9999 9999 9999 9999 9999 9999 9999 9999
					9999 9999 9999 9999 9999 9999 9999 9999 9999 9999 9999 9999 9999 9999 9999 9999 9999 9999 9999 9999 9999 9999 9999 9999 9999 9999 9999 9999 9999 9999
					9999 9999 9999 9999 9999 9999 9999 9999 9999 9999 9999 9999 9999 9999 9999 9999 9999 9999 9999 9999 9999 9999 9999 9999 9999 9999 9999 9999 9999 9999
					9999 9999 9999 9999 9999 9999 9999 9999 9999 9999 9999 9999 9999 9999 9999 9999 9999 9999 9999 9999 9999 9999 9999 9999 9999 9999 9999 9999 9999 9999
					9999 9999 9999 9999 9999 9999 9999 9999 9999 9999 9999 9999 9999 9999 9999 9999 9999 9999 9999 9999 9999 9999 9999 9999 9999 9999 9999 9999 9999 9999
					9999 9999 9999 9999 9999 9999 9999 9999 9999 9999 9999 9999 9999 9999 9999 9999 9999 9999 9999 9999 9999 9999 9999 9999 9999 9999 9999 9999 9999 9999
					9999 9999 9999 9999 9999 9999 9999 9999 9999 9999 9999 9999 9999 9999 9999 9999 9999 9999 9999 9999 9999 9999 9999 9999 9999 9999 9999 9999 9999 9999
					9999 9999 9999 9999 9999 9999 9999 9999 9999 9999 9999 9999 9999 9999 9999 9999 9999 9999 9999 9999 9999 9999 9999 9999 9999 9999 9999 9999 9999 9999
					9999 9999 9999 9999 9999 9999 9999 9999 9999 9999 9999 9999 9999 9999 9999 9999 9999 9999 9999 9999 9999 9999 9999 9999 9999 9999 9999 9999 9999 9999
					9999 9999 9999 9999 9999 9999 9999 9999 9999 9999 9999 9999 9999 9999 9999 9999 9999 9999 9999 9999 9999 9999 9999 9999 9999 9999 9999 9999 9999 9999
					9999 9999 9999 9999 9999 9999 9999 9999 9999 9999 9999 9999 9999 9999 9999 9999 9999 9999 9999 9999 9999 9999 9999 9999 9999 9999 9999 9999 9999 9999
					9999 9999 9999 9999 9999 9999 9999 9999 9999 9999 9999 9999 9999 9999 9999 9999 9999 9999 9999 9999 9999 9999 9999 9999 9999 9999 9999 9999 9999 9999
					9999 9999 9999 9999 9999 9999 9999 9999 9999 9999 9999 9999 9999 9999 9999 9999 9999 9999 9999 9999 9999 9999 9999 9999 9999 9999 9999 9999 9999 9999>;
				huawei,rx_to_rx_limit =
					<9999 9999 9999 9999 9999 9999 9999 9999 9999 9999 9999 9999 9999 9999 9999 9999 9999 9999 9999 9999 9999 9999 9999 9999 9999 9999 9999 9999 9999
					9999 9999 9999 9999 9999 9999 9999 9999 9999 9999 9999 9999 9999 9999 9999 9999 9999 9999 9999 9999 9999 9999 9999 9999 9999 9999 9999 9999 9999
					9999 9999 9999 9999 9999 9999 9999 9999 9999 9999 9999 9999 9999 9999 9999 9999 9999 9999 9999 9999 9999 9999 9999 9999 9999 9999 9999 9999 9999
					9999 9999 9999 9999 9999 9999 9999 9999 9999 9999 9999 9999 9999 9999 9999 9999 9999 9999 9999 9999 9999 9999 9999 9999 9999 9999 9999 9999 9999
					9999 9999 9999 9999 9999 9999 9999 9999 9999 9999 9999 9999 9999 9999 9999 9999 9999 9999 9999 9999 9999 9999 9999 9999 9999 9999 9999 9999 9999
					9999 9999 9999 9999 9999 9999 9999 9999 9999 9999 9999 9999 9999 9999 9999 9999 9999 9999 9999 9999 9999 9999 9999 9999 9999 9999 9999 9999 9999
					9999 9999 9999 9999 9999 9999 9999 9999 9999 9999 9999 9999 9999 9999 9999 9999 9999 9999 9999 9999 9999 9999 9999 9999 9999 9999 9999 9999 9999
					9999 9999 9999 9999 9999 9999 9999 9999 9999 9999 9999 9999 9999 9999 9999 9999 9999 9999 9999 9999 9999 9999 9999 9999 9999 9999 9999 9999 9999
					9999 9999 9999 9999 9999 9999 9999 9999 9999 9999 9999 9999 9999 9999 9999 9999 9999 9999 9999 9999 9999 9999 9999 9999 9999 9999 9999 9999 9999
					9999 9999 9999 9999 9999 9999 9999 9999 9999 9999 9999 9999 9999 9999 9999 9999 9999 9999 9999 9999 9999 9999 9999 9999 9999 9999 9999 9999 9999
					9999 9999 9999 9999 9999 9999 9999 9999 9999 9999 9999 9999 9999 9999 9999 9999 9999 9999 9999 9999 9999 9999 9999 9999 9999 9999 9999 9999 9999
					9999 9999 9999 9999 9999 9999 9999 9999 9999 9999 9999 9999 9999 9999 9999 9999 9999 9999 9999 9999 9999 9999 9999 9999 9999 9999 9999 9999 9999
					9999 9999 9999 9999 9999 9999 9999 9999 9999 9999 9999 9999 9999 9999 9999 9999 9999 9999 9999 9999 9999 9999 9999 9999 9999 9999 9999 9999 9999
					9999 9999 9999 9999 9999 9999 9999 9999 9999 9999 9999 9999 9999 9999 9999 9999 9999 9999 9999 9999 9999 9999 9999 9999 9999 9999 9999 9999 9999
					9999 9999 9999 9999 9999 9999 9999 9999 9999 9999 9999 9999 9999 9999 9999 9999 9999 9999 9999 9999 9999 9999 9999 9999 9999 9999 9999 9999 9999
					9999 9999 9999 9999 9999 9999 9999 9999 9999 9999 9999 9999 9999 9999 9999 9999 9999 9999 9999 9999 9999 9999 9999 9999 9999 9999 9999 9999 9999
					9999 9999 9999 9999 9999 9999 9999 9999 9999 9999 9999 9999 9999 9999 9999 9999 9999 9999 9999 9999 9999 9999 9999 9999 9999 9999 9999 9999 9999
					9999 9999 9999 9999 9999 9999 9999 9999 9999 9999 9999 9999 9999 9999 9999 9999 9999 9999 9999 9999 9999 9999 9999 9999 9999 9999 9999 9999 9999>;

			};
			huawei,tianma{
				huawei,name = "huawei,tianma";
				huawei,report_rate_test = <1>; /* 0:disable test, 1:enable test */
				// if is config item is set to 1, the mmi test will always return pass
				huawei,mmi_test_always_pass = <0>;

				huawei,highres_upperlimit = <9999 9999 9999>;
				huawei,highres_lowerlimit = <0xD8F1 0xD8F1 0xD8F1>;/* 0xD8F1 == -9999 */

				huawei,rx_cap_upperlimit = <9999>;
				huawei,rx_cap_lowerlimit = <0xD8F1>;

				huawei,tx_cap_upperlimit = <9999>;
				huawei,tx_cap_lowerlimit = <0xD8F1>;

				huawei,deltarawimage_upperlimit = <40>;
				huawei,deltarawimage_lowerlimit = <0xFFD8>; /* 0xFFD8 == -40 */

				huawei,f51_ctrl_01_low_sensitivity_val = <0x1b>;
				huawei,f51_ctrl_04_low_sensitivity_val = <0x17>;
				huawei,f01_ctrl_05_low_sensitivity_val = <0x05>;
				huawei,f01_ctrl_09_low_sensitivity_val = <0x04>;

				huawei,roi_control_addr_offset = <12>;
				huawei,roi_control_bit = <0>;
				huawei,roi_data_addr_offset = <0>;

				huawei,holster_switch_offset = <9>;
				huawei,set_effective_window_offset = <8>;
				huawei,support_set_window = <0>;
				huawei,support_td43xxshort_test = <0>;

				huawei,fullraw_upperlimit =
					<2146 1955 2032 1901 1991 2023 2033 1949 1986 1928 1855 1914 1837 1802 2159 1985 1879 1874 1830 1772 1901 1814 1788 1865 1824 1776 1882 1824 1802 1914
					2021 1843 1945 1824 1907 1949 1951 1834 1837 1810 1711 1771 1698 1752 1916 1794 1736 1794 1759 1698 1820 1738 1710 1784 1738 1699 1807 1750 1722 1792
					1888 1692 1813 1726 1788 1801 1805 1704 1782 1706 1687 1711 1694 1769 1811 1794 1764 1799 1765 1708 1829 1746 1715 1801 1752 1699 1814 1748 1706 1782
					1822 1626 1718 1576 1637 1652 1668 1608 1753 1652 1682 1715 1698 1768 1805 1783 1769 1806 1776 1717 1834 1756 1727 1810 1760 1703 1818 1748 1702 1783
					1818 1634 1696 1535 1580 1622 1637 1607 1706 1672 1685 1727 1704 1734 1805 1790 1775 1824 1784 1726 1840 1768 1736 1811 1764 1702 1814 1748 1711 1788
					1837 1661 1699 1554 1573 1637 1649 1622 1722 1688 1692 1740 1710 1727 1813 1748 1736 1840 1790 1730 1852 1776 1744 1807 1769 1696 1811 1748 1710 1806
					1878 1687 1710 1615 1591 1657 1664 1638 1736 1698 1702 1753 1721 1776 1824 1759 1745 1848 1802 1744 1864 1780 1746 1811 1772 1699 1810 1750 1710 1843
					1951 1722 1872 1897 1867 1775 1664 1640 1740 1699 1702 1757 1726 1768 1822 1894 1846 1846 1802 1745 1865 1778 1745 1813 1775 1702 1810 1744 1702 1862
					2006 1778 1879 1906 1998 1940 1714 1654 1661 1666 1706 1696 1691 1756 1930 1960 1867 1776 1752 1744 1790 1730 1744 1738 1724 1699 1736 1696 1696 1799
					2077 1807 1753 1920 1939 1956 1876 1645 1661 1680 1729 1813 1876 1848 2012 1993 1825 1715 1736 1679 1775 1714 1706 1699 1668 1718 1745 1715 1646 1694
					2135 1849 1579 1820 1949 1930 1962 1727 1652 1768 2009 1967 2006 1936 1986 2040 1780 1711 1811 1727 1788 1865 1752 1704 1769 1855 1759 1802 1704 1694
					2110 1855 1760 1805 1771 1871 1956 1738 1640 1916 2084 1978 2009 1928 1769 1794 1775 1711 1907 1945 1878 1914 1752 1711 1805 1878 1799 1806 1776 1765
					2110 1883 1860 1955 1825 1811 1944 1757 1631 1936 2081 1968 2020 1936 1734 1837 1794 1706 2093 2005 1909 1962 1748 1710 1776 1760 1710 1805 1970 1817
					2093 1840 1871 1967 1895 1778 1913 1741 1829 1795 2005 1916 1926 1760 1691 1848 1883 1784 2152 2020 1939 1902 1744 1710 1778 1752 1706 1943 2082 1885
					2090 1740 1830 1949 1868 1848 1825 1841 1913 1933 1937 1910 1906 1692 1684 1778 1879 1813 2068 1979 1841 1778 1726 1706 1776 1740 1708 1981 2110 1932
					2068 1760 1598 1820 1836 1832 1790 1872 1906 1943 1939 1882 1974 1814 1718 1784 1788 1750 1974 1814 1830 1985 1841 1722 1775 1730 1711 2009 2100 1951
					1987 1748 1511 1627 1631 1660 1817 1879 1897 1936 1921 1886 2010 1939 1811 1822 1788 1682 1993 1846 2033 2082 1910 1795 1764 1718 1706 1846 1956 1757
					1872 1637 1589 1634 1631 1682 1860 1910 1920 1956 1960 1921 2054 2023 1966 1943 1886 1757 1830 2009 2105 2155 2036 1792 1855 1810 1805 1904 1836 1878>;

				huawei,fullraw_lowerlimit =
					<936 804 849 845 849 890 885 851 916 880 886 933 908 864 936 933 885 943 954 890 924 914 896 913 914 887 924 890 909 923
					872 740 794 791 791 830 824 798 870 834 839 890 867 819 895 890 844 908 918 850 890 880 862 875 875 847 894 862 870 867
					875 748 798 798 798 838 834 806 879 845 850 903 878 829 905 901 847 913 918 852 892 882 862 879 879 847 892 852 864 854
					880 747 802 798 798 839 836 810 882 850 852 907 882 834 906 905 852 918 923 862 898 886 866 883 885 851 896 860 862 867
					883 757 810 809 806 849 847 821 892 864 865 918 890 842 914 909 862 918 926 864 900 887 867 883 885 851 893 852 865 875
					885 759 814 811 809 851 850 822 894 865 866 918 890 844 914 910 860 918 926 865 898 886 866 883 885 849 894 851 866 890
					885 767 824 823 817 865 864 830 901 875 872 926 898 849 918 911 860 918 924 862 898 886 864 882 882 847 890 850 865 898
					882 770 828 828 823 869 869 834 906 878 874 924 895 847 915 910 851 914 920 854 894 882 862 878 879 842 886 845 851 892
					846 786 798 806 834 826 834 842 862 850 878 885 870 846 873 883 849 870 892 850 845 849 854 830 844 842 842 819 849 851
					959 854 859 873 882 857 924 878 929 906 898 924 952 895 962 938 920 946	933 938 952 949 918 938 939 910 942 944 916 964
					1005 865 842 903 900 846  962 903 922 946 924 920 993 921 957 982 950 950 982 969 952 997 950 938 1003 956 943 1000 952 954
					1002 849 819 883 880 831 946 890 913 931 920 913 992 920 956 982 950 954 985 974 954 999 952 952 1008 969 948 1006 959 954
					999 836	815 878 874 822 942 880 903 926 915 908 990 914 952 982 950 954 985 974 954 1000 956 950 1012 970 950 1010 966 951
					999 849	810 883 869 823 941 882 905 920 914 905 987 913 946 982 950 952 984 974 956 1002 957 951 1013 969 954 1010 969 943
					999 844	810 873 874 819 936 875 901 916 909 900 986 911 946 979 949 946 979 967 954 1000 957 946 1012 962 951 1006 965 929
					999 839	802 875 872 818 930 875 898 908 908 895 984 908 941 980 950 941 978 965 956 1002 957 943 1012 964 954 1003 964 929
					1002 838 814 875 873 815 931 870 895 913 907 890 979 906 941 977 950 934 974 962 956 1002 956 937 1003 954 951 1002 965 931
					1053 895 862 923 918 864 976 915 944 956 982 937 1028 957 987 1034 1006 987 1031 1018 1013 1059 1015 994 1066 1016 1014 1070 1043 1036>;
				huawei,tx_to_tx_limit =
					<250 250 250 250 250 250 250 250 250 250 250 250 250 250 250 250 250 250 250 250 250 250 250 250 250 250 250 250 250 250
					150 150 150 150 150 150 150 150 150 150 150 150 150 150 150 150 150 150 150 150 150 150 150 150 150 150 150 150 150 150
					150 150 150 150 150 150 150 150 150 150 150 150 150 150 150 150 150 150 150 150 150 150 150 150 150 150 150 150 150 150
					150 150 150 150 150 150 150 150 150 150 150 150 150 150 150 150 150 150 150 150 150 150 150 150 150 150 150 150 150 150
					200 200 200 200 200 200 200 200 200 200 200 200 200 200 200 200 200 200 200 200 200 200 200 200 200 200 200 200 200 200
					200 200 200 200 200 200 200 200 200 200 200 200 200 200 200 200 200 200 200 200 200 200 200 200 200 200 200 200 200 200
					200 200 200 200 200 200 200 200 200 200 200 200 200 200 200 200 200 200 200 200 200 200 200 200 200 200 200 200 200 200
					250 250 250 250 250 250 250 250 250 250 250 250 250 250 250 250 250 250 250 250 250 250 250 250 250 250 250 250 250 250
					300 300 300 300 300 300 300 300 300 300 300 300 300 300 300 300 300 300 300 300 300 300 300 300 300 300 300 300 300 300
					300 300 300 300 300 300 300 300 300 300 300 300 300 300 300 300 300 300 300 300 300 300 300 300 300 300 300 300 300 300
					200 200 200 200 200 200 200 200 200 200 200 200 200 200 200 200 200 200 200 200 200 200 200 200 200 200 200 200 200 200
					200 200 200 200 200 200 200 200 200 200 200 200 200 200 200 200 200 200 200 200 200 200 200 200 200 200 200 200 200 200
					200 200 200 200 200 200 200 200 200 200 200 200 200 200 200 200 200 200 200 200 200 200 200 200 200 200 200 200 200 200
					150 150 150 150 150 150 150 150 150 150 150 150 150 150 150 150 150 150 150 150 150 150 150 150 150 150 150 150 150 150
					150 150 150 150 150 150 150 150 150 150 150 150 150 150 150 150 150 150 150 150 150 150 150 150 150 150 150 150 150 150
					150 150 150 150 150 150 150 150 150 150 150 150 150 150 150 150 150 150 150 150 150 150 150 150 150 150 150 150 150 150
					350 350 350 350 350 350 350 350 350 350 350 350 350 350 350 350 350 350 350 350 350 350 350 350 350 350 350 350 350 350>;
				huawei,rx_to_rx_limit =
					<600 400 400 400 400 400 400 400 400 400 400 400 400 400 400 400 400 400 400 400 400 400 400 400 400 400 400 400 400
					600 400 400 400 400 400 400 400 400 400 400 400 400 400 400 400 400 400 400 400 400 400 400 400 400 400 400 400 400
					600 400 400 400 400 400 400 400 400 400 400 400 400 400 400 400 400 400 400 400 400 400 400 400 400 400 400 400 400
					600 400 400 400 400 400 400 400 400 400 400 400 400 400 400 400 400 400 400 400 400 400 400 400 400 400 400 400 400
					600 400 400 400 400 400 400 400 400 400 400 400 400 400 400 400 400 400 400 400 400 400 400 400 400 400 400 400 400
					600 400 400 400 400 400 400 400 400 400 400 400 400 400 400 400 400 400 400 400 400 400 400 400 400 400 400 400 400
					600 400 400 400 400 400 400 400 400 400 400 400 400 400 400 400 400 400 400 400 400 400 400 400 400 400 400 400 400
					600 400 400 400 400 400 400 400 400 400 400 400 400 400 400 400 400 400 400 400 400 400 400 400 400 400 400 400 400
					600 400 400 400 400 400 400 400 400 400 400 400 400 400 400 400 400 400 400 400 400 400 400 400 400 400 400 400 400
					600 400 400 400 400 400 400 400 400 400 400 400 400 400 400 400 400 400 400 400 400 400 400 400 400 400 400 400 400
					600 400 400 400 400 400 400 400 400 400 400 400 400 400 400 400 400 400 400 400 400 400 400 400 400 400 400 400 400
					600 400 400 400 400 400 400 400 400 400 400 400 400 400 400 400 400 400 400 400 400 400 400 400 400 400 400 400 400
					600 400 400 400 400 400 400 400 400 400 400 400 400 400 400 400 400 400 400 400 400 400 400 400 400 400 400 400 400
					600 400 400 400 400 400 400 400 400 400 400 400 400 400 400 400 400 400 400 400 400 400 400 400 400 400 400 400 400
					600 400 400 400 400 400 400 400 400 400 400 400 400 400 400 400 400 400 400 400 400 400 400 400 400 400 400 400 400
					600 400 400 400 400 400 400 400 400 400 400 400 400 400 400 400 400 400 400 400 400 400 400 400 400 400 400 400 400
					600 400 400 400 400 400 400 400 400 400 400 400 400 400 400 400 400 400 400 400 400 400 400 400 400 400 400 400 400
					600 400 400 400 400 400 400 400 400 400 400 400 400 400 400 400 400 400 400 400 400 400 400 400 400 400 400 400 400>;
			};
			huawei,lg {
				huawei,name = "huawei,lg";
				huawei,report_rate_test = <0>; /* 0:disable test, 1:enable test */
				// if is config item is set to 1, the mmi test will always return pass
				huawei,mmi_test_always_pass = <0>;

				huawei,highres_upperlimit = <9999 9999 9999>;
				huawei,highres_lowerlimit = <0xD8F1 0xD8F1 0xD8F1>;/* 0xD8F1 == -9999 */

				huawei,rx_cap_upperlimit = <9999>;
				huawei,rx_cap_lowerlimit = <0xD8F1>;

				huawei,tx_cap_upperlimit = <9999>;
				huawei,tx_cap_lowerlimit = <0xD8F1>;

				huawei,deltarawimage_upperlimit = <40>;
				huawei,deltarawimage_lowerlimit = <0xFFD8>; /* 0xFFD8 == -40 */

				huawei,f51_ctrl_01_low_sensitivity_val = <0x1b>;
				huawei,f51_ctrl_04_low_sensitivity_val = <0x17>;
				huawei,f01_ctrl_05_low_sensitivity_val = <0x05>;
				huawei,f01_ctrl_09_low_sensitivity_val = <0x04>;

				huawei,roi_control_addr_offset = <12>;
				huawei,roi_control_bit = <0>;
				huawei,roi_data_addr_offset = <0>;

				huawei,holster_switch_offset = <9>;
				huawei,set_effective_window_offset = <8>;
				huawei,support_set_window = <0>;
				huawei,support_td43xxshort_test = <1>;

				huawei,fullraw_upperlimit =
					<1892 1854 1754 1793 1838 1752 1773 1838 1739 1782 1816 1738 1747 1815 1700 1750 1751 1669 1664 1698 1580 1612 1613 1547 1521 1578 1446 1486 1502 1491
					1687 1749 1652 1694 1742 1659 1680 1746 1651 1694 1730 1654 1663 1730 1619 1667 1672 1590 1587 1625 1508 1542 1546 1478 1455 1515 1378 1422 1439 1427
					1667 1736 1641 1684 1733 1650 1672 1738 1642 1687 1725 1650 1664 1732 1617 1669 1676 1593 1591 1632 1513 1551 1555 1489 1464 1525 1388 1430 1448 1440
					1664 1733 1638 1681 1730 1647 1669 1736 1639 1685 1723 1646 1659 1726 1615 1667 1673 1587 1589 1629 1512 1547 1552 1486 1463 1525 1388 1429 1448 1439
					1655 1723 1629 1673 1723 1639 1663 1730 1634 1680 1717 1645 1660 1728 1615 1668 1681 1598 1599 1646 1530 1570 1577 1512 1487 1552 1416 1459 1477 1472
					1652 1717 1629 1672 1721 1638 1663 1729 1633 1678 1717 1642 1656 1723 1611 1665 1677 1591 1595 1642 1528 1568 1577 1509 1491 1556 1416 1461 1479 1474
					1651 1715 1620 1665 1716 1633 1658 1725 1630 1676 1716 1642 1658 1725 1613 1665 1684 1603 1607 1652 1542 1581 1594 1530 1512 1577 1439 1483 1503 1499
					1658 1716 1624 1664 1717 1634 1660 1724 1632 1674 1716 1641 1655 1721 1612 1664 1682 1600 1603 1650 1542 1580 1594 1530 1515 1577 1442 1486 1508 1504
					1595 1633 1617 1596 1619 1628 1583 1613 1628 1620 1632 1639 1602 1642 1615 1615 1613 1612 1568 1585 1557 1547 1535 1554 1489 1528 1477 1473 1469 1551
					1619 1581 1615 1607 1578 1607 1596 1582 1603 1612 1576 1616 1590 1593 1609 1612 1559 1600 1563 1544 1544 1547 1494 1524 1490 1468 1451 1473 1418 1533
					1606 1633 1699 1611 1634 1697 1599 1641 1691 1616 1629 1702 1589 1643 1690 1609 1602 1673 1550 1585 1615 1533 1526 1596 1466 1515 1520 1444 1448 1582
					1600 1629 1698 1608 1634 1697 1599 1638 1691 1616 1632 1703 1590 1646 1693 1611 1602 1674 1551 1587 1619 1535 1530 1599 1468 1513 1521 1443 1448 1581
					1603 1634 1703 1615 1638 1703 1604 1646 1697 1620 1633 1706 1591 1646 1693 1609 1596 1668 1543 1578 1607 1522 1513 1582 1447 1494 1498 1422 1422 1554
					1607 1637 1703 1620 1642 1704 1608 1646 1698 1622 1638 1708 1594 1648 1695 1612 1596 1668 1539 1574 1598 1511 1500 1567 1431 1477 1482 1404 1405 1530
					1611 1646 1713 1625 1645 1711 1612 1648 1700 1625 1637 1710 1594 1650 1694 1612 1591 1663 1533 1565 1586 1500 1487 1552 1417 1461 1464 1387 1386 1508
					1616 1654 1720 1630 1652 1716 1616 1654 1704 1628 1642 1712 1596 1651 1697 1613 1593 1663 1530 1561 1580 1492 1477 1541 1407 1451 1455 1375 1374 1491
					1632 1660 1726 1639 1661 1725 1624 1661 1711 1634 1645 1716 1600 1655 1698 1616 1593 1661 1529 1559 1576 1489 1473 1535 1400 1443 1446 1369 1365 1482
					1726 1745 1810 1723 1742 1804 1707 1742 1791 1716 1726 1795 1681 1734 1777 1697 1673 1741 1608 1635 1652 1564 1547 1608 1477 1521 1525 1450 1450 1586>;
				huawei,fullraw_lowerlimit =
					<1019 998 944 965 990 944 955 990 937 960 978 936 941 977 916 942 943 899 896 914 851 868 869 833 819 850 778 800 809 803
					909 942 890 912 938 893 904 940 889 912 932 890 895 932 872 897 900 856 855 875 812 830 832 796 783 816 742 766 775 769
					897 935 883 907 933 888 900 936 884 909 929 888 896 932 871 899 902 858 857 879 815 835 837 802 788 821 748 770 780 776
					896 933 882 905 932 887 899 935 883 907 928 886 893 930 869 897 901 855 855 877 814 833 836 800 788 821 748 769 780 775
					891 928 877 901 928 883 895 932 880 904 925 886 894 930 869 898 905 860 861 886 824 846 849 814 801 836 762 785 795 792
					890 925 877 900 927 882 895 931 879 904 925 884 892 928 867 897 903 857 859 884 823 844 849 813 803 838 762 787 797 794
					889 923 872 897 924 879 893 929 878 902 924 884 893 929 869 897 907 863 865 890 830 851 858 824 814 849 775 799 809 807
					893 924 874 896 925 880 894 928 879 902 924 883 891 927 868 896 906 862 863 888 830 851 858 824 816 849 776 800 812 810
					859 879 871 860 872 876 853 869 876 872 879 883 862 884 869 869 869 868 844 853 839 833 827 837 802 823 795 793 791 835
					872 851 869 865 850 865 860 852 863 868 848 870 856 858 867 868 839 862 841 832 832 833 804 820 802 790 781 793 764 825
					865 879 915 867 880 914 861 883 911 870 877 916 855 885 910 867 862 901 834 853 869 825 822 860 790 816 818 778 780 852
					862 877 914 866 880 914 861 882 911 870 879 917 856 886 911 867 862 902 835 855 872 827 824 861 790 815 819 777 780 851
					863 880 917 869 882 917 864 886 914 872 879 918 857 886 911 867 860 898 831 850 865 820 815 852 779 804 806 766 766 837
					865 881 917 872 884 918 866 886 914 874 882 920 858 888 913 868 860 898 829 848 860 813 808 844 771 795 798 756 757 824
					867 886 923 875 886 921 868 888 916 875 881 921 858 888 912 868 857 895 825 843 854 808 801 836 763 787 788 747 746 812
					870 890 926 878 890 924 870 890 918 876 884 922 860 889 914 869 858 895 824 841 851 804 795 830 757 781 783 741 740 803
					879 894 930 883 895 929 874 895 921 880 886 924 862 891 914 870 858 895 823 839 848 802 793 827 754 777 778 737 735 798
					930 939 974 928 938 972 919 938 965 924 930 967 905 934 957 914 901 937 866 881 890 842 833 866 795 819 821 781 781 854>;
				huawei,tx_to_tx_limit =
					<350 250 250 250 250 250 250 250 250 250 250 250 250 250 250 250 250 250 250 250 250 250 250 250 250 250 250 250 250 250
					150 150 150 150 150 150 150 150 150 150 150 150 150 150 150 150 150 150 150 150 150 150 150 150 150 150 150 150 150 150
					150 150 150 150 150 150 150 150 150 150 150 150 150 150 150 150 150 150 150 150 150 150 150 150 150 150 150 150 150 150
					150 150 150 150 150 150 150 150 150 150 150 150 150 150 150 150 150 150 150 150 150 150 150 150 150 150 150 150 150 150
					150 150 150 150 150 150 150 150 150 150 150 150 150 150 150 150 150 150 150 150 150 150 150 150 150 150 150 150 150 150
					150 150 150 150 150 150 150 150 150 150 150 150 150 150 150 150 150 150 150 150 150 150 150 150 150 150 150 150 150 150
					150 150 150 150 150 150 150 150 150 150 150 150 150 150 150 150 150 150 150 150 150 150 150 150 150 150 150 150 150 150
					250 250 250 250 250 250 250 250 250 250 250 250 250 250 250 250 250 250 250 250 250 250 250 250 250 250 250 250 250 250
					300 300 300 300 300 300 300 300 300 300 300 300 300 300 300 300 300 300 300 300 300 300 300 300 300 300 300 300 300 300
					150 150 150 150 150 150 150 150 150 150 150 150 150 150 150 150 150 150 150 150 150 150 150 150 150 150 150 150 150 150
					150 150 150 150 150 150 150 150 150 150 150 150 150 150 150 150 150 150 150 150 150 150 150 150 150 150 150 150 150 150
					150 150 150 150 150 150 150 150 150 150 150 150 150 150 150 150 150 150 150 150 150 150 150 150 150 150 150 150 150 150
					150 150 150 150 150 150 150 150 150 150 150 150 150 150 150 150 150 150 150 150 150 150 150 150 150 150 150 150 150 150
					150 150 150 150 150 150 150 150 150 150 150 150 150 150 150 150 150 150 150 150 150 150 150 150 150 150 150 150 150 150
					150 150 150 150 150 150 150 150 150 150 150 150 150 150 150 150 150 150 150 150 150 150 150 150 150 150 150 150 150 150
					150 150 150 150 150 150 150 150 150 150 150 150 150 150 150 150 150 150 150 150 150 150 150 150 150 150 150 150 150 150
					250 250 250 250 250 250 250 250 250 250 250 250 250 250 250 250 250 250 250 250 250 250 250 250 250 250 250 250 250 250>;
				huawei,rx_to_rx_limit =
					<400 400 400 400 400 400 400 400 400 400 400 400 400 400 400 400 400 400 400 400 400 400 400 400 400 400 400 400 400
					400 400 400 400 400 400 400 400 400 400 400 400 400 400 400 400 400 400 400 400 400 400 400 400 400 400 400 400 400
					400 400 400 400 400 400 400 400 400 400 400 400 400 400 400 400 400 400 400 400 400 400 400 400 400 400 400 400 400
					400 400 400 400 400 400 400 400 400 400 400 400 400 400 400 400 400 400 400 400 400 400 400 400 400 400 400 400 400
					400 400 400 400 400 400 400 400 400 400 400 400 400 400 400 400 400 400 400 400 400 400 400 400 400 400 400 400 400
					400 400 400 400 400 400 400 400 400 400 400 400 400 400 400 400 400 400 400 400 400 400 400 400 400 400 400 400 400
					400 400 400 400 400 400 400 400 400 400 400 400 400 400 400 400 400 400 400 400 400 400 400 400 400 400 400 400 400
					400 400 400 400 400 400 400 400 400 400 400 400 400 400 400 400 400 400 400 400 400 400 400 400 400 400 400 400 400
					400 400 400 400 400 400 400 400 400 400 400 400 400 400 400 400 400 400 400 400 400 400 400 400 400 400 400 400 400
					400 400 400 400 400 400 400 400 400 400 400 400 400 400 400 400 400 400 400 400 400 400 400 400 400 400 400 400 400
					400 400 400 400 400 400 400 400 400 400 400 400 400 400 400 400 400 400 400 400 400 400 400 400 400 400 400 400 400
					400 400 400 400 400 400 400 400 400 400 400 400 400 400 400 400 400 400 400 400 400 400 400 400 400 400 400 400 400
					400 400 400 400 400 400 400 400 400 400 400 400 400 400 400 400 400 400 400 400 400 400 400 400 400 400 400 400 400
					400 400 400 400 400 400 400 400 400 400 400 400 400 400 400 400 400 400 400 400 400 400 400 400 400 400 400 400 400
					400 400 400 400 400 400 400 400 400 400 400 400 400 400 400 400 400 400 400 400 400 400 400 400 400 400 400 400 400
					400 400 400 400 400 400 400 400 400 400 400 400 400 400 400 400 400 400 400 400 400 400 400 400 400 400 400 400 400
					400 400 400 400 400 400 400 400 400 400 400 400 400 400 400 400 400 400 400 400 400 400 400 400 400 400 400 400 400
					400 400 400 400 400 400 400 400 400 400 400 400 400 400 400 400 400 400 400 400 400 400 400 400 400 400 400 400 400>;
			};
		};
	};

	/*To disable gen-vkeys.c probe,avoid generate kobject*/
	gen-vkeys {
		compatible = "huawei,gen-vkeys";
		label = "synaptics_rmi4_i2c";
		qcom,disp-maxx = <720>;
		qcom,disp-maxy = <1280>;
		qcom,panel-maxx = <720>;
		qcom,panel-maxy = <1369>;
		qcom,key-codes = <158 172 139>;
	};

};
